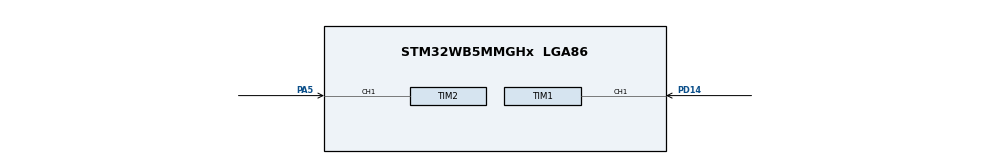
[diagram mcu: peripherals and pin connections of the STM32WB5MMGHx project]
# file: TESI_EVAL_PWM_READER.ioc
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Mcu.Family=STM32WB
Mcu.Name=STM32WB5MMGHx
Mcu.Package=LGA86
NVIC.PriorityGroup=NVIC_PRIORITYGROUP_4
NVIC.TIM1_CC_IRQn=true\:0\:0\:false\:false\:true\:true\:true\:true
NVIC.TIM2_IRQn=true\:0\:0\:false\:false\:true\:true\:true\:true
PA13.Mode=Serial_Wire
PA13.Signal=SYS_JTMS-SWDIO
PA14.Mode=Serial_Wire
PA14.Signal=SYS_JTCK-SWCLK
PA5.Signal=S_TIM2_CH1
PD14.Signal=S_TIM1_CH1
ProjectManager.HeapSize=0x200
ProjectManager.StackSize=0x400
ProjectManager.TargetToolchain=STM32CubeIDE
RCC.APB3Freq_Value=16000000
RCC.HSE_VALUE=32000000
RCC.HSI48_VALUE=48000000
RCC.HSI_VALUE=16000000
RCC.VCOOutputFreq_Value=32000000
SH.S_TIM1_CH1.0=TIM1_CH1,Input_Capture1_from_TI1
SH.S_TIM2_CH1.0=TIM2_CH1,Input_Capture1_from_TI1
TIM1.Channel-Input_Capture1_from_TI1=TIM_CHANNEL_1
TIM1.Channel-Input_Capture2_from_TI1_63=TIM_CHANNEL_2
TIM1.ICPolarity_CH2=TIM_INPUTCHANNELPOLARITY_FALLING
TIM1.Prescaler=40-1
TIM2.Channel-Input_Capture1_from_TI1=TIM_CHANNEL_1
TIM2.Channel-Input_Capture2_from_TI1_63=TIM_CHANNEL_2
TIM2.ICPolarity_CH2=TIM_INPUTCHANNELPOLARITY_FALLING
TIM2.Period=4294967295
TIM2.Prescaler=80-1
VP_MEMORYMAP_VS_MEMORYMAP.Mode=CurAppReg
VP_TIM1_VS_indirect_ch1.Mode=Input_Capture2_from_TI1_63
VP_TIM2_VS_indirect_ch1.Mode=Input_Capture2_from_TI1_63
board=custom

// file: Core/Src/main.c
/* USER CODE BEGIN Header */
/**
 ******************************************************************************
 * @file           : main.c
 * @brief          : Main program body
 ******************************************************************************
 * @attention
 *
 * Copyright (c) 2025 STMicroelectronics.
 * All rights reserved.
 *
 * This software is licensed under terms that can be found in the LICENSE file
 * in the root directory of this software component.
 * If no LICENSE file comes with this software, it is provided AS-IS.
 *
 ******************************************************************************
 */
/* USER CODE END Header */
#include "main.h"

/* USER CODE BEGIN Includes */
#include "pwmsignal.h"
/* USER CODE END Includes */

TIM_HandleTypeDef htim1;
TIM_HandleTypeDef htim2;

/* USER CODE BEGIN PV */
PWMSignal pwm1;
PWMSignal pwm2;

uint32_t freq1, duty1, freq2, duty2;
/* USER CODE END PV */

void SystemClock_Config(void);
void PeriphCommonClock_Config(void);
static void MX_GPIO_Init(void);
static void MX_TIM1_Init(void);
static void MX_TIM2_Init(void);

int main(void)
{

	/* MCU Configuration--------------------------------------------------------*/

	/* Reset of all peripherals, Initializes the Flash interface and the Systick. */
	HAL_Init();

	/* Configure the system clock */
	SystemClock_Config();

	/* Configure the peripherals common clocks */
	PeriphCommonClock_Config();

	/* Initialize all configured peripherals */
	MX_GPIO_Init();
	MX_TIM1_Init();
	MX_TIM2_Init();
	/* USER CODE BEGIN 2 */

	// INIZIALIZZAZIONE INTERRUPT
	//TIMER 1
	HAL_TIM_IC_Start_IT(&htim1, TIM_CHANNEL_1); // PD14		-->		D3
	HAL_TIM_IC_Start_IT(&htim1, TIM_CHANNEL_2);
	// TIMER 2
	HAL_TIM_IC_Start_IT(&htim2, TIM_CHANNEL_1); // PA5		-->		A2
	HAL_TIM_IC_Start_IT(&htim2, TIM_CHANNEL_2);

	// INIZIALIZZAZIONE SEGNALE PWM 1 e 2
	initialisePWMSignal(&pwm1, 4000000L, 40, 1);
	initialisePWMSignal(&pwm2, 4000000L, 80, 0);
	/* USER CODE END 2 */

	/* Infinite loop */
	/* USER CODE BEGIN WHILE */

	while (1)
	{
//		HAL_Delay(300);
		freq1 = getFrequency(&pwm1);
		duty1 = getDutyCycle(&pwm1);
		freq2 = getFrequency(&pwm2);
		duty2 = getDutyCycle(&pwm2);
		/* USER CODE END WHILE */

	}
}

void SystemClock_Config(void)
{
	RCC_OscInitTypeDef RCC_OscInitStruct =
	{ 0 };
	RCC_ClkInitTypeDef RCC_ClkInitStruct =
	{ 0 };

	/** Configure the main internal regulator output voltage
	 */
	__HAL_PWR_VOLTAGESCALING_CONFIG(PWR_REGULATOR_VOLTAGE_SCALE1);

	/** Initializes the RCC Oscillators according to the specified parameters
	 * in the RCC_OscInitTypeDef structure.
	 */
	RCC_OscInitStruct.OscillatorType = RCC_OSCILLATORTYPE_HSI | RCC_OSCILLATORTYPE_MSI;
	RCC_OscInitStruct.HSIState = RCC_HSI_ON;
	RCC_OscInitStruct.MSIState = RCC_MSI_ON;
	RCC_OscInitStruct.HSICalibrationValue = RCC_HSICALIBRATION_DEFAULT;
	RCC_OscInitStruct.MSICalibrationValue = RCC_MSICALIBRATION_DEFAULT;
	RCC_OscInitStruct.MSIClockRange = RCC_MSIRANGE_6;
	RCC_OscInitStruct.PLL.PLLState = RCC_PLL_NONE;
	if (HAL_RCC_OscConfig(&RCC_OscInitStruct) != HAL_OK)
	{
		Error_Handler();
	}

	/** Configure the SYSCLKSource, HCLK, PCLK1 and PCLK2 clocks dividers
	 */
	RCC_ClkInitStruct.ClockType = RCC_CLOCKTYPE_HCLK4 | RCC_CLOCKTYPE_HCLK2 | RCC_CLOCKTYPE_HCLK | RCC_CLOCKTYPE_SYSCLK
			| RCC_CLOCKTYPE_PCLK1 | RCC_CLOCKTYPE_PCLK2;
	RCC_ClkInitStruct.SYSCLKSource = RCC_SYSCLKSOURCE_MSI;
	RCC_ClkInitStruct.AHBCLKDivider = RCC_SYSCLK_DIV1;
	RCC_ClkInitStruct.APB1CLKDivider = RCC_HCLK_DIV1;
	RCC_ClkInitStruct.APB2CLKDivider = RCC_HCLK_DIV1;
	RCC_ClkInitStruct.AHBCLK2Divider = RCC_SYSCLK_DIV1;
	RCC_ClkInitStruct.AHBCLK4Divider = RCC_SYSCLK_DIV1;

	if (HAL_RCC_ClockConfig(&RCC_ClkInitStruct, FLASH_LATENCY_0) != HAL_OK)
	{
		Error_Handler();
	}
}

void PeriphCommonClock_Config(void)
{
	RCC_PeriphCLKInitTypeDef PeriphClkInitStruct =
	{ 0 };

	/** Initializes the peripherals clock
	 */
	PeriphClkInitStruct.PeriphClockSelection = RCC_PERIPHCLK_SMPS;
	PeriphClkInitStruct.SmpsClockSelection = RCC_SMPSCLKSOURCE_HSI;
	PeriphClkInitStruct.SmpsDivSelection = RCC_SMPSCLKDIV_RANGE1;

	if (HAL_RCCEx_PeriphCLKConfig(&PeriphClkInitStruct) != HAL_OK)
	{
		Error_Handler();
	}
}

static void MX_TIM1_Init(void)
{

	TIM_MasterConfigTypeDef sMasterConfig =
	{ 0 };
	TIM_IC_InitTypeDef sConfigIC =
	{ 0 };

	htim1.Instance = TIM1;
	htim1.Init.Prescaler = 40 - 1;
	htim1.Init.CounterMode = TIM_COUNTERMODE_UP;
	htim1.Init.Period = 65535;
	htim1.Init.ClockDivision = TIM_CLOCKDIVISION_DIV1;
	htim1.Init.RepetitionCounter = 0;
	htim1.Init.AutoReloadPreload = TIM_AUTORELOAD_PRELOAD_DISABLE;
	if (HAL_TIM_IC_Init(&htim1) != HAL_OK)
	{
		Error_Handler();
	}
	sMasterConfig.MasterOutputTrigger = TIM_TRGO_RESET;
	sMasterConfig.MasterOutputTrigger2 = TIM_TRGO2_RESET;
	sMasterConfig.MasterSlaveMode = TIM_MASTERSLAVEMODE_DISABLE;
	if (HAL_TIMEx_MasterConfigSynchronization(&htim1, &sMasterConfig) != HAL_OK)
	{
		Error_Handler();
	}
	sConfigIC.ICPolarity = TIM_INPUTCHANNELPOLARITY_RISING;
	sConfigIC.ICSelection = TIM_ICSELECTION_DIRECTTI;
	sConfigIC.ICPrescaler = TIM_ICPSC_DIV1;
	sConfigIC.ICFilter = 0;
	if (HAL_TIM_IC_ConfigChannel(&htim1, &sConfigIC, TIM_CHANNEL_1) != HAL_OK)
	{
		Error_Handler();
	}
	sConfigIC.ICPolarity = TIM_INPUTCHANNELPOLARITY_FALLING;
	sConfigIC.ICSelection = TIM_ICSELECTION_INDIRECTTI;
	if (HAL_TIM_IC_ConfigChannel(&htim1, &sConfigIC, TIM_CHANNEL_2) != HAL_OK)
	{
		Error_Handler();
	}

}

static void MX_TIM2_Init(void)
{

	TIM_MasterConfigTypeDef sMasterConfig =
	{ 0 };
	TIM_IC_InitTypeDef sConfigIC =
	{ 0 };

	htim2.Instance = TIM2;
	htim2.Init.Prescaler = 80 - 1;
	htim2.Init.CounterMode = TIM_COUNTERMODE_UP;
	htim2.Init.Period = 4294967295;
	htim2.Init.ClockDivision = TIM_CLOCKDIVISION_DIV1;
	htim2.Init.AutoReloadPreload = TIM_AUTORELOAD_PRELOAD_DISABLE;
	if (HAL_TIM_IC_Init(&htim2) != HAL_OK)
	{
		Error_Handler();
	}
	sMasterConfig.MasterOutputTrigger = TIM_TRGO_RESET;
	sMasterConfig.MasterSlaveMode = TIM_MASTERSLAVEMODE_DISABLE;
	if (HAL_TIMEx_MasterConfigSynchronization(&htim2, &sMasterConfig) != HAL_OK)
	{
		Error_Handler();
	}
	sConfigIC.ICPolarity = TIM_INPUTCHANNELPOLARITY_RISING;
	sConfigIC.ICSelection = TIM_ICSELECTION_DIRECTTI;
	sConfigIC.ICPrescaler = TIM_ICPSC_DIV1;
	sConfigIC.ICFilter = 0;
	if (HAL_TIM_IC_ConfigChannel(&htim2, &sConfigIC, TIM_CHANNEL_1) != HAL_OK)
	{
		Error_Handler();
	}
	sConfigIC.ICPolarity = TIM_INPUTCHANNELPOLARITY_FALLING;
	sConfigIC.ICSelection = TIM_ICSELECTION_INDIRECTTI;
	if (HAL_TIM_IC_ConfigChannel(&htim2, &sConfigIC, TIM_CHANNEL_2) != HAL_OK)
	{
		Error_Handler();
	}

}

static void MX_GPIO_Init(void)
{

	/* GPIO Ports Clock Enable */
	__HAL_RCC_GPIOA_CLK_ENABLE();
	__HAL_RCC_GPIOD_CLK_ENABLE();

}

/* USER CODE BEGIN 4 */
void HAL_TIM_IC_CaptureCallback(TIM_HandleTypeDef *htim)
{
	if (htim->Instance == TIM1)
	{
		switch (htim->Channel)
		{
			case HAL_TIM_ACTIVE_CHANNEL_1:
				computeFrequency(&pwm1, htim, TIM_CHANNEL_1, 1);
				break;
			case HAL_TIM_ACTIVE_CHANNEL_2:
				computeFrequency(&pwm1, htim, TIM_CHANNEL_2, 0);
				break;
			default:
				break;
		}
	}
	else if (htim->Instance == TIM2)
	{
		switch (htim->Channel)
		{
			case HAL_TIM_ACTIVE_CHANNEL_1:
				computeFrequency(&pwm2, htim, TIM_CHANNEL_1, 1);
				break;
			case HAL_TIM_ACTIVE_CHANNEL_2:
				computeFrequency(&pwm2, htim, TIM_CHANNEL_2, 0);
				break;
			default:
				break;
		}
	}
}
/* USER CODE END 4 */

void Error_Handler(void)
{
	__disable_irq();
	while (1)
	{
	}
}
